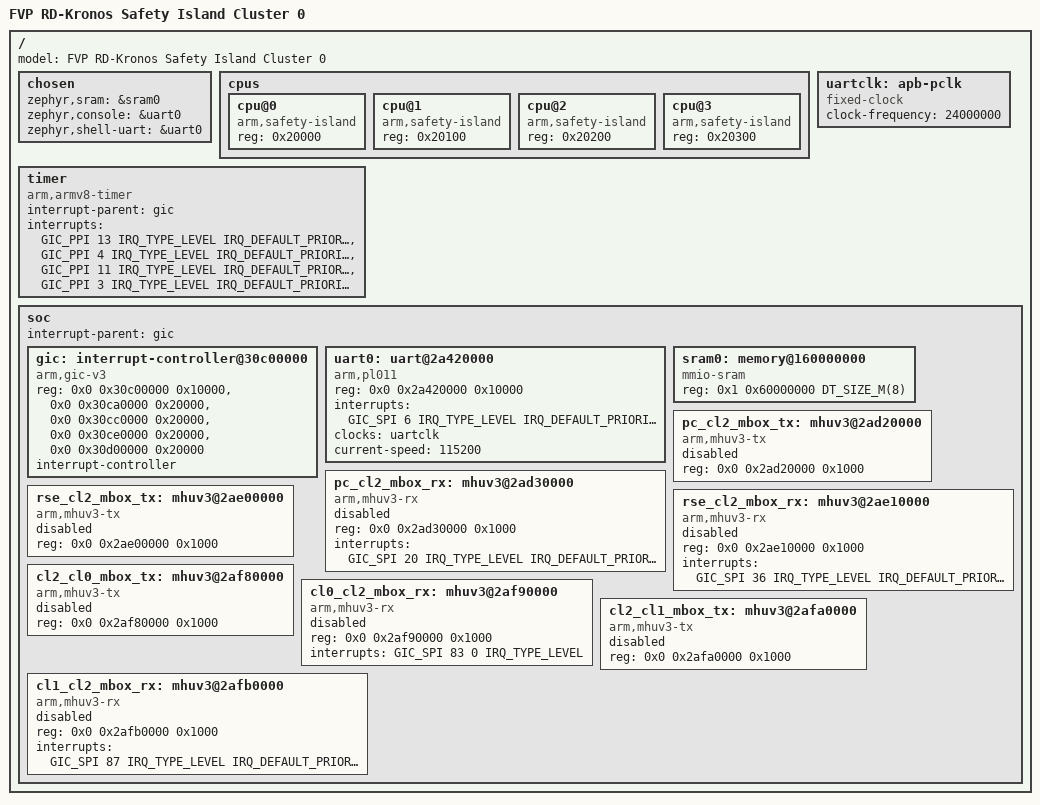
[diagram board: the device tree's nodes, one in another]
/*
 * SPDX-FileCopyrightText: <text>Copyright 2023-2024 Arm Limited and/or its
 * affiliates <open-source-office@arm.com></text>
 *
 * SPDX-License-Identifier: Apache-2.0
 */

/dts-v1/;

#include <mem.h>
#include <arm64/armv8-r.dtsi>
#include <dt-bindings/interrupt-controller/arm-gic.h>
#include "fvp_rd_kronos_safety_island_device_mem.dtsi"

/ {
	#address-cells = <2>;
	#size-cells = <1>;
	model = "FVP RD-Kronos Safety Island Cluster 0";

	chosen {
		zephyr,sram = &sram0;
		zephyr,console = &uart0;
		zephyr,shell-uart = &uart0;
	};

	cpus {
		#address-cells = <1>;
		#size-cells = <0>;

		cpu@0 {
			device_type = "cpu";
			compatible = "arm,safety-island";
			reg = <0x20000>;
		};

		cpu@1 {
			device_type = "cpu";
			compatible = "arm,safety-island";
			reg = <0x20100>;
		};

		cpu@2 {
			device_type = "cpu";
			compatible = "arm,safety-island";
			reg = <0x20200>;
		};

		cpu@3 {
			device_type = "cpu";
			compatible = "arm,safety-island";
			reg = <0x20300>;
		};

	};

	timer {
		compatible = "arm,armv8-timer";
		interrupt-parent = <&gic>;
		interrupts = <GIC_PPI 13 IRQ_TYPE_LEVEL
			      IRQ_DEFAULT_PRIORITY>,
			     <GIC_PPI 4 IRQ_TYPE_LEVEL
			      IRQ_DEFAULT_PRIORITY>,
			     <GIC_PPI 11 IRQ_TYPE_LEVEL
			      IRQ_DEFAULT_PRIORITY>,
			     <GIC_PPI 3 IRQ_TYPE_LEVEL
			      IRQ_DEFAULT_PRIORITY>;
	};

	uartclk: apb-pclk {
		compatible = "fixed-clock";
		clock-frequency = <24000000>;
		#clock-cells = <0>;
	};

	soc {
		#address-cells = <2>;
		#size-cells = <1>;
		interrupt-parent = <&gic>;

		gic: interrupt-controller@30c00000 {
			compatible = "arm,gic-v3", "arm,gic";
			reg = <0x0 0x30c00000 0x10000>,
			      <0x0 0x30ca0000 0x20000>,
			      <0x0 0x30cc0000 0x20000>,
			      <0x0 0x30ce0000 0x20000>,
			      <0x0 0x30d00000 0x20000>;
			interrupt-controller;
			#interrupt-cells = <4>;
			status = "okay";
		};

		uart0: uart@2a420000 {
			compatible = "arm,pl011";
			reg = <0x0 0x2a420000 0x10000>;
			status = "disabled";
			interrupts = <GIC_SPI 6 IRQ_TYPE_LEVEL IRQ_DEFAULT_PRIORITY>;
			interrupt-names = "irq_0";
			clocks = <&uartclk>;
		};

		sram0: memory@160000000 {
			compatible = "mmio-sram";
			reg = <0x1 0x60000000 DT_SIZE_M(8)>;
		};

		pc_cl2_mbox_tx: mhuv3@2ad20000 {
			compatible = "arm,mhuv3-tx";
			#mbox-cells = <1>;
			reg = <0x0 0x2ad20000 0x1000>;
			status = "disabled";
		};

		pc_cl2_mbox_rx: mhuv3@2ad30000 {
			compatible = "arm,mhuv3-rx";
			#mbox-cells = <1>;
			reg = <0x0 0x2ad30000 0x1000>;
			interrupts = <GIC_SPI 20 IRQ_TYPE_LEVEL IRQ_DEFAULT_PRIORITY>;
			interrupt-names = "rx";
			status = "disabled";
		};

		rse_cl2_mbox_tx: mhuv3@2ae00000 {
			compatible = "arm,mhuv3-tx";
			#mbox-cells = <1>;
			reg = <0x0 0x2ae00000 0x1000>;
			status = "disabled";
		};

		rse_cl2_mbox_rx: mhuv3@2ae10000 {
			compatible = "arm,mhuv3-rx";
			#mbox-cells = <1>;
			reg = <0x0 0x2ae10000 0x1000>;
			interrupts = <GIC_SPI 36 IRQ_TYPE_LEVEL IRQ_DEFAULT_PRIORITY>;
			interrupt-names = "rx";
			status = "disabled";
		};

		cl2_cl0_mbox_tx: mhuv3@2af80000 {
			compatible = "arm,mhuv3-tx";
			#mbox-cells = <1>;
			reg = <0x0 0x2af80000 0x1000>;
			status = "disabled";
		};

		cl0_cl2_mbox_rx: mhuv3@2af90000 {
			compatible = "arm,mhuv3-rx";
			#mbox-cells = <1>;
			reg = <0x0 0x2af90000 0x1000>;
			interrupts = <GIC_SPI 83 0 IRQ_TYPE_LEVEL>;
			interrupt-names = "rx";
			status = "disabled";
		};

		cl2_cl1_mbox_tx: mhuv3@2afa0000 {
			compatible = "arm,mhuv3-tx";
			#mbox-cells = <1>;
			reg = <0x0 0x2afa0000 0x1000>;
			status = "disabled";
		};

		cl1_cl2_mbox_rx: mhuv3@2afb0000 {
			compatible = "arm,mhuv3-rx";
			#mbox-cells = <1>;
			reg = <0x0 0x2afb0000 0x1000>;
			interrupts = <GIC_SPI 87 IRQ_TYPE_LEVEL IRQ_DEFAULT_PRIORITY>;
			interrupt-names = "rx";
			status = "disabled";
		};
	};
};

&uart0 {
	status = "okay";
	current-speed = <115200>;
};
